# EFR32FG23B010F512IM48 register map
Vendor: Silicon Labs; Series: EFR32; File version: C
CPU: CM33 r0p4, little endian, MPU, FPU, DSP, VTOR, 4 interrupt priority bits, 8 SAU regions
Registers are 32-bit, read-write, reset 0x0 unless marked. A register's access mark holds for its fields unless they carry their own. Offsets are from the block's base; [hi:lo] are bit positions; lines under a group give offsets from that group; 'fields as' and 'values as' point back to an identical list.

## VDAC0_NS — VDAC0_NS Registers
Base 0x59024000
Same registers: VDAC0_S 0x49024000
0x00 IPVERSION ro reset 0x1
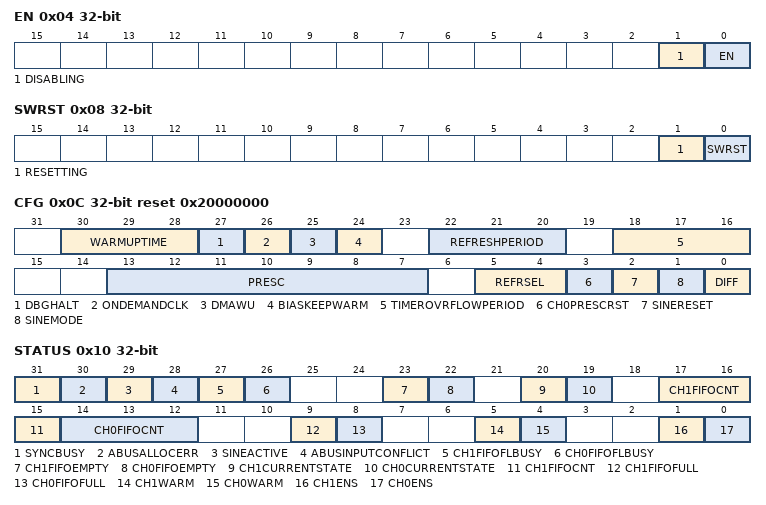
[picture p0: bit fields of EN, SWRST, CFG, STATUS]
0x04 EN
  [1] DISABLING ro — Disablement busy status
  [0] EN — VDAC Module Enable
    0=DISABLE; 1=ENABLE
0x08 SWRST
  [1] RESETTING ro — Software reset busy status
  [0] SWRST wo — Software reset command
0x0C CFG reset 0x20000000
  [30:28] WARMUPTIME — DAC Warmup Time
  [27] DBGHALT — Debug Halt
    0=NORMAL (Continue operation as normal during debug mode); 1=HALT (Complete the current conversion and then halt during debug mode)
  [26] ONDEMANDCLK — Always allow clk_dac
  [25] DMAWU — VDAC DMA Wakeup
  [24] BIASKEEPWARM — Bias Keepwarm Mode Enable
  [22:20] REFRESHPERIOD — Refresh Timer Overflow Period
    0=CYCLES2 (All channels with enabled refresh are refreshed every 2 CLK_REFRESH cycles); 1=CYCLES4 (All channels with enabled refresh are refreshed every 4 CLK_REFRESH cycles); 2=CYCLES8 (All channels with enabled refresh are refreshed every 8 CLK_REFRESH cycles); 3=CYCLES16 (All channels with enabled refresh are refreshed every 16 CLK_REFRESH cycles); 4=CYCLES32 (All channels with enabled refresh are refreshed every 32 CLK_REFRESH cycles); 5=CYCLES64 (All channels with enabled refresh are refreshed every 64 CLK_REFRESH cycles); 6=CYCLES128 (All channels with enabled refresh are refreshed every 128 CLK_REFRESH cycles); 7=CYCLES256 (All channels with enabled refresh are refreshed every 256 CLK_REFRESH cycles)
  [18:16] TIMEROVRFLOWPERIOD — Internal Timer Overflow Period
    0=CYCLES2 (The Timer overflows every 2 Prescaled CLK_DAC cycles); 1=CYCLES4 (The Timer overflows every 4 Prescaled CLK_DAC cycles); 2=CYCLES8 (The Timer overflows every 8 Prescaled CLK_DAC cycles); 3=CYCLES16 (The Timer overflows every 16 Prescaled CLK_DAC cycles); 4=CYCLES32 (The Timer overflows every 32 Prescaled CLK_DAC cycles); 5=CYCLES64 (The Timer overflows every 64 Prescaled CLK_DAC cycles)
  [13:7] PRESC — Prescaler Setting for DAC clock
  [5:4] REFRSEL — Reference Selection
    0=V125 (Internal 1.25 V bandgap reference); 1=V25 (Internal 2.5 V bandgap reference); 2=VDD (AVDD reference); 3=EXT (External pin reference)
  [3] CH0PRESCRST — Channel 0 Start Reset Prescaler
    0=NORESETPRESC (Prescaler not reset on channel 0 start); 1=RESETPRESC (Prescaler reset on channel 0 start)
  [2] SINERESET — Sine Wave Reset When inactive
  [1] SINEMODE
    0=DISSINEMODE (Sine mode disabled. Sine reset to 0 degrees); 1=ENSINEMODE (Sine mode enabled)
  [0] DIFF — Differential Mode
    0=SINGLEENDED (Single ended output); 1=DIFFERENTIAL (Differential output)
0x10 STATUS ro
  [31] SYNCBUSY — Sync Busy Combined
  [30] ABUSALLOCERR — ABUS Allocation Error Status
  [29] SINEACTIVE — Sine Wave Output Status on Channel
  [28] ABUSINPUTCONFLICT — ABUS Input Conflict Status
  [27] CH1FIFOFLBUSY — CH1 FIFO Flush Sync Busy
  [26] CH0FIFOFLBUSY — CH0 FIFO Flush Sync Busy
  [23] CH1FIFOEMPTY — Channel 1 FIFO Empty Status
  [22] CH0FIFOEMPTY — Channel 0 FIFO Empty Status
  [20] CH1CURRENTSTATE — Channel 1 Current Status
  [19] CH0CURRENTSTATE — Channel 0 Current Status
  [17:15] CH1FIFOCNT — Channel 1 FIFO Valid Count
  [14:12] CH0FIFOCNT — Channel 0 FIFO Valid Count
  [9] CH1FIFOFULL — Channel 1 FIFO Full Status
  [8] CH0FIFOFULL — Channel 0 FIFO Full Status
  [5] CH1WARM — Channel 1 Warmed Status
  [4] CH0WARM — Channel 0 Warmed Status
  [1] CH1ENS — Channel 1 Enabled Status
  [0] CH0ENS — Channel 0 Enabled Status
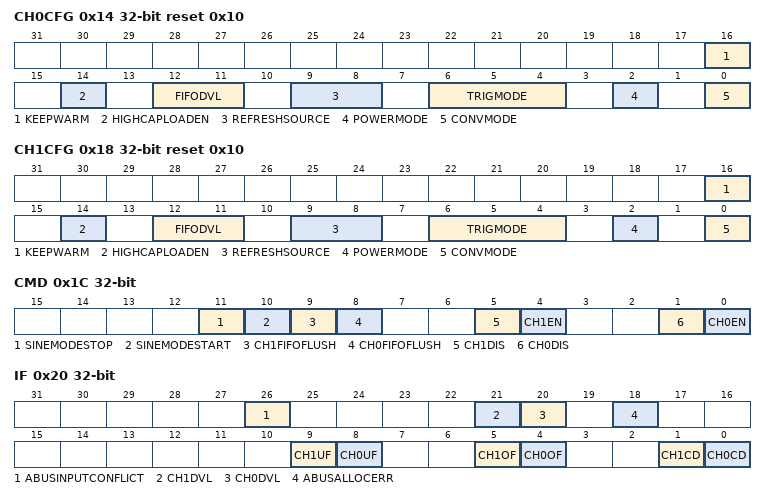
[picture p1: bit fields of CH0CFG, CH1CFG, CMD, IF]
0x14 CH0CFG reset 0x10
  [16] KEEPWARM — Channel 0 Keepwarm Mode Enable
  [14] HIGHCAPLOADEN — Channel 0 High Cap Load Mode Enable
  [12:11] FIFODVL — Channel 0 FIFO Low Watermark
  [9:8] REFRESHSOURCE — Channel 0 Refresh Source
    0=NONE (No Refresh Source Selected for Channel 0.); 1=REFRESHTIMER (Channel 0 Refresh triggered by Refresh Timer Overflow); 2=SYNCPRS (Channel 0 Refresh triggered by Sync PRS. PRS Trigger should have the same clock group as VDAC.); 3=ASYNCPRS (Channel 0 Refresh triggered by Async PRS)
  [6:4] TRIGMODE — Channel 0 Trigger Mode
    0=NONE (No Conversion Trigger Source Selected for Channel 0); 1=SW (Channel 0 is triggered by Channel 0 FIFO (CH0F) write); 2=SYNCPRS (Channel 0 is triggered by Sync PRS input. PRS Trigger should have the same clock group as VDAC.); 3=LESENSE (Channel 0 is triggered by LESENSE); 4=INTERNALTIMER (Channel 0 is triggered by Internal Timer Overflow); 5=ASYNCPRS (Channel 0 is triggered by Async PRS input)
  [2] POWERMODE — Channel 0 Power Mode
    0=HIGHPOWER (Default is High Power Mode); 1=LOWPOWER (Set this bit for Low Power Mode)
  [0] CONVMODE — Channel 0 Conversion Mode
    0=CONTINUOUS (DAC channel 0 is set in continuous mode); 1=SAMPLEOFF (DAC channel 0 is set in sample/shut off mode)
0x18 CH1CFG reset 0x10
  [16] KEEPWARM — Channel 1 Keepwarm Mode Enable
  [14] HIGHCAPLOADEN — Channel 1 High Cap Load Mode Enable
  [12:11] FIFODVL — Channel 1 FIFO Low Watermark
  [9:8] REFRESHSOURCE — Channel 1 Refresh Source
    0=NONE (No Refresh Source Selected); 1=REFRESHTIMER (CH1 Refresh Triggered by Refresh Timer Overflow); 2=SYNCPRS (CH1 Refresh Triggered by Sync PRS. PRS Trigger should have the same clock group as VDAC.); 3=ASYNCPRS (CH1 Refresh Triggered by Async PRS)
  [6:4] TRIGMODE — Channel 1 Trigger Mode
    0=NONE (No Conversion Trigger Source Selected for Channel 1); 1=SW (Channel 1 is triggered by Channel 1 FIFO (CH1F) write); 2=SYNCPRS (Channel 1 is triggered by Sync PRS input.PRS Trigger should have the same clock group as VDAC.); 4=INTERNALTIMER (Channel 1 is triggered by Internal Timer Overflow); 5=ASYNCPRS (Channel 1 is triggered by Async PRS input)
  [2] POWERMODE — Channel 1 Power Mode
    values as CH0CFG.POWERMODE
  [0] CONVMODE — Channel 1 Conversion Mode
    0=CONTINUOUS (DAC channel 1 is set in continuous mode); 1=SAMPLEOFF (DAC channel 1 is set in sample/shut off mode)
0x1C CMD wo
  [11] SINEMODESTOP — Stop Sine Wave Generation
  [10] SINEMODESTART — Start Sine Wave Generation
  [9] CH1FIFOFLUSH — CH1 WFIFO Flush
  [8] CH0FIFOFLUSH — CH0 WFIFO Flush
  [5] CH1DIS — DAC Channel 1 Disable
  [4] CH1EN — DAC Channel 1 Enable
  [1] CH0DIS — DAC Channel 0 Disable
  [0] CH0EN — DAC Channel 0 Enable
0x20 IF
  [26] ABUSINPUTCONFLICT — ABUS Input Conflict Error Flag
  [21] CH1DVL — CH1 Data Valid Level Interrupt Flag
  [20] CH0DVL — CH0 Data Valid Level Interrupt Flag
  [18] ABUSALLOCERR — ABUS Port Allocation Error Flag
  [9] CH1UF — CH1 Data Underflow Interrupt Flag
  [8] CH0UF — CH0 Data Underflow Interrupt Flag
  [5] CH1OF — CH1 Data Overflow Interrupt Flag
  [4] CH0OF — CH0 Data Overflow Interrupt Flag
  [1] CH1CD — CH1 Conversion Done Interrupt Flag
  [0] CH0CD — CH0 Conversion Done Interrupt Flag
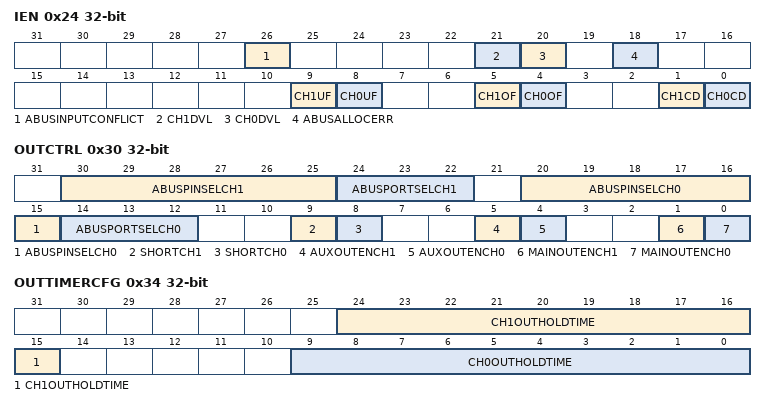
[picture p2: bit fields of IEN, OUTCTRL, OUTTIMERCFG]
0x24 IEN
  [26] ABUSINPUTCONFLICT — ABUS Input Conflict Interrupt Flag
  [21] CH1DVL — CH1 Data Valid Level Interrupt Flag
  [20] CH0DVL — CH0 Data Valid Level Interrupt Flag
  [18] ABUSALLOCERR — ABUS Allocation Error Interrupt Flag
  [9] CH1UF — CH1 Data Underflow Interrupt Flag
  [8] CH0UF — CH0 Data Underflow Interrupt Flag
  [5] CH1OF — CH1 Data Overflow Interrupt Flag
  [4] CH0OF — CH0 Data Overflow Interrupt Flag
  [1] CH1CD — CH1 Conversion Done Interrupt Flag
  [0] CH0CD — CH0 Conversion Done Interrupt Flag
0x28 CH0F wo
  [11:0] DATA — Channel 0 Data
0x2C CH1F wo
  [11:0] DATA — Channel 1 Data
0x30 OUTCTRL
  [30:25] ABUSPINSELCH1 — CH1 ABUS Pin Select
  [24:22] ABUSPORTSELCH1 — CH1 ABUS Port Select
    0=NONE (No GPIO Selected for CH1 ABUS Output); 1=PORTA (Port A Selected); 2=PORTB (Port B Selected); 3=PORTC (Port C Selected); 4=PORTD (Port D Selected)
  [20:15] ABUSPINSELCH0 — CH0 ABUS Pin Select
  [14:12] ABUSPORTSELCH0 — CH0 ABUS Port Select
    0=NONE (No GPIO Selected for CH0 ABUS Output); 1=PORTA (Port A Selected); 2=PORTB (Port B Selected); 3=PORTC (Port C Selected); 4=PORTD (Port D Selected)
  [9] SHORTCH1 — CH0 Main and Alternative Output Short
  [8] SHORTCH0 — CH1 Main and Alternative Output Short
  [5] AUXOUTENCH1 — CH1 Alternative Output Enable
  [4] AUXOUTENCH0 — CH0 Alternative Output Enable
  [1] MAINOUTENCH1 — CH1 Main Output Enable
  [0] MAINOUTENCH0 — CH0 Main Output Enable
0x34 OUTTIMERCFG
  [24:15] CH1OUTHOLDTIME — CH1 Output Hold Time
  [9:0] CH0OUTHOLDTIME — CH0 Output Hold Time
